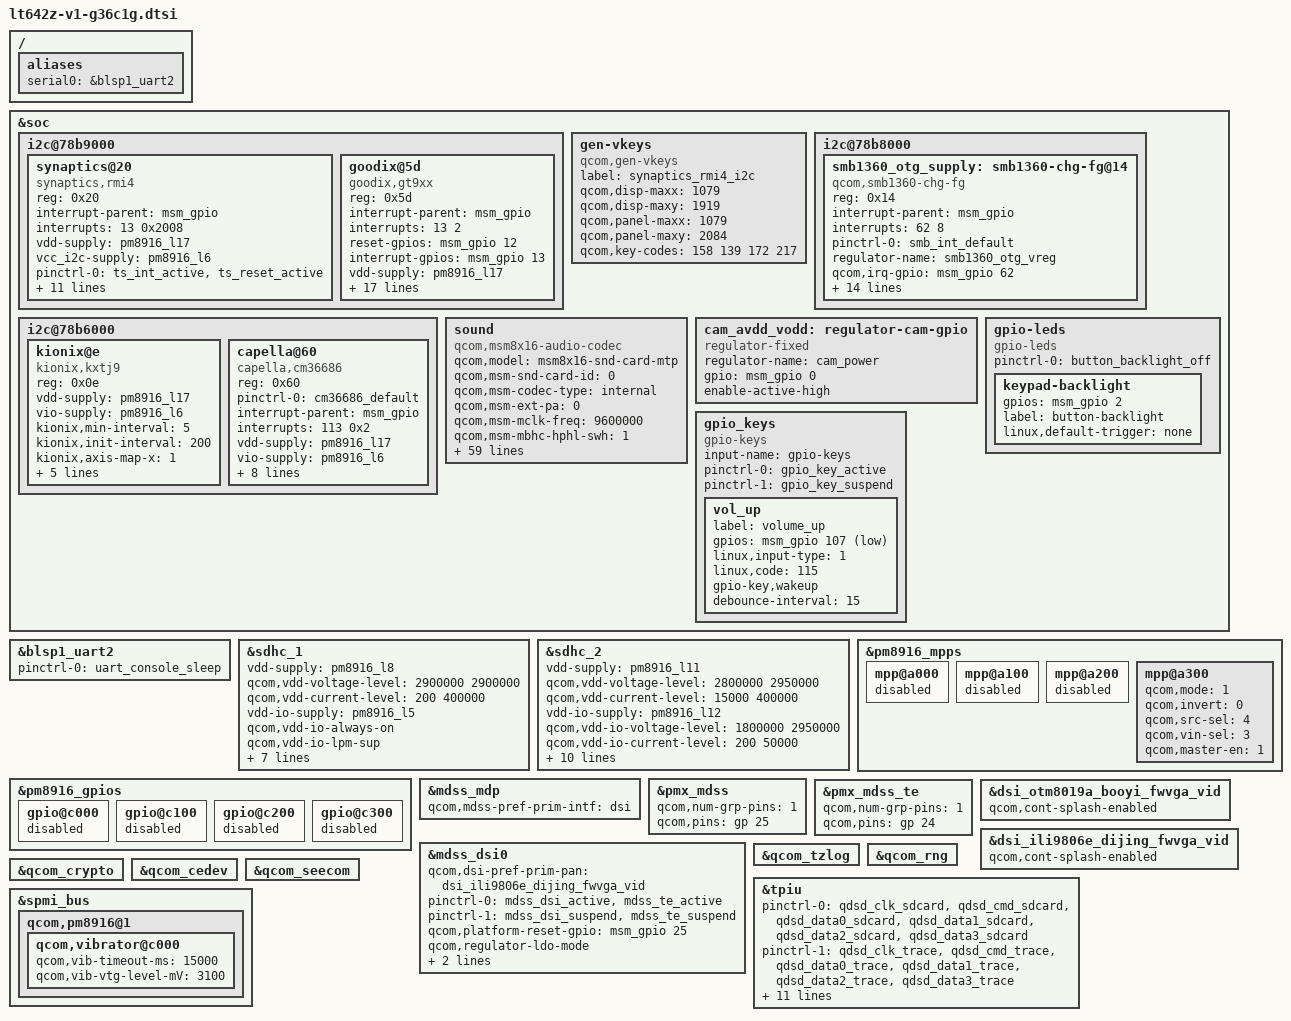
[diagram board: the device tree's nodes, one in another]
/* Copyright (c) 2014, The Linux Foundation. All rights reserved.
 *
 * This program is free software; you can redistribute it and/or modify
 * it under the terms of the GNU General Public License version 2 and
 * only version 2 as published by the Free Software Foundation.
 *
 * This program is distributed in the hope that it will be useful,
 * but WITHOUT ANY WARRANTY; without even the implied warranty of
 * MERCHANTABILITY or FITNESS FOR A PARTICULAR PURPOSE.  See the
 * GNU General Public License for more details.
 */

#include "msm8916-pinctrl.dtsi"
#include "msm8916-camera-sensor-mtp.dtsi"

/ {
	aliases {
		serial0 = &blsp1_uart2;
	};
};

&soc {
	i2c@78b9000 { /* BLSP1 QUP5 */
		synaptics@20 {
			compatible = "synaptics,rmi4";
			reg = <0x20>;
			interrupt-parent = <&msm_gpio>;
			interrupts = <13 0x2008>;
			vdd-supply = <&pm8916_l17>;
			vcc_i2c-supply = <&pm8916_l6>;
			/* pins used by touchscreen */
			pinctrl-names = "pmx_ts_active","pmx_ts_suspend","pmx_ts_suspend";
			pinctrl-0 = <&ts_int_active &ts_reset_active>;
			pinctrl-1 = <&ts_int_suspend &ts_reset_suspend>;
			pinctrl-2 = <&ts_release>;
			synaptics,display-coords = <0 0 1079 1919>;
			synaptics,panel-coords = <0 0 1079 2084>;
			synaptics,irq-gpio = <&msm_gpio 13 0x2008>;
			synaptics,reset-gpio = <&msm_gpio 12 0x0>;
			synaptics,i2c-pull-up;
			synaptics,power-down;
			synaptics,disable-gpios;
			/* Underlying clocks used by secure touch */
			clocks = <&clock_gcc clk_gcc_blsp1_ahb_clk>,
			 <&clock_gcc clk_gcc_blsp1_qup5_i2c_apps_clk>;
			clock-names = "iface_clk", "core_clk";
		};
	        goodix@5d {
			compatible = "goodix,gt9xx";
			reg = <0x5d>;
			interrupt-parent = <&msm_gpio>;
			interrupts = <13 2>;
			reset-gpios = <&msm_gpio 12 0x00>;
			interrupt-gpios = <&msm_gpio 13 0x00>;
			vdd-supply = <&pm8916_l17>;
			vcc-i2c-supply = <&pm8916_l6>;
			pinctrl-names = "pmx_ts_active","pmx_ts_suspend";
			pinctrl-0 = <&ts_int_active &ts_reset_active>;
			pinctrl-1 = <&ts_int_suspend &ts_reset_suspend>;
			goodix,panel-coords = <0 0 480 854>;
			goodix,display-coords = <0 0 480 854>;
			goodix,button-map= <139 172 158>;
			goodix,product-id = "9157";
			goodix,rawdata-key0 = <14 8 4100 1200>;
			goodix,rawdata-key1 = <14 8 2000 600>;
			goodix,cfg-data0 = [//dijing
				 42 E0 01 56 03 0A 05 41 01 08 28 08 50 32 03 05 00 00 1D 7E 00 00 00 00 00 00 00 8A 29 0A 28 2A D3 07 00 00 00 9B 33 1D 00 00 00 00 00 00 00 32 00 00 2B 28 46 94 D5 02 07 14 00 04 7A 2A 00 6E 2F 00 65 34 00 5A 3B 00 51 42 00 51 10 30 48 00 F0 4A 3A FF FF 27 00 00 00 00 00 00 00 00 00 00 00 00 00 00 00 00 00 00 00 00 00 00 05 00 46 28 02 04 06 08 0A 0C 0E 10 12 14 FF FF FF FF 1F FF FF FF FF FF FF FF FF 00 00 19 00 00 FF FF 22 21 20 1F 1E 1D 1C 16 18 04 12 0F 08 0A 0C 06 10 02 00 FF FF FF FF FF FF FF 00 00 00 FC FF FF FF FF FF FF FF CF FF FF FF FF 13 01];

			goodix,cfg-data1 = [//zhenghai
				 42 E0 01 56 03 0A 05 41 01 08 28 08 50 32 03 05 00 00 1D 7E 00 00 00 00 00 00 00 8A 29 0A 28 2A D3 07 00 00 00 9B 33 1D 00 00 00 00 00 00 00 32 00 00 2B 28 46 94 D5 02 07 14 00 04 7A 2A 00 6E 2F 00 65 34 00 5A 3B 00 51 42 00 51 10 30 48 00 F0 4A 3A FF FF 27 00 00 00 00 00 00 00 00 00 00 00 00 00 00 00 00 00 00 00 00 00 00 05 00 46 28 02 04 06 08 0A 0C 0E 10 12 14 FF FF FF FF 1F FF FF FF FF FF FF FF FF 00 00 19 00 00 FF FF 22 21 20 1F 1E 1D 1C 16 18 04 12 0F 08 0A 0C 06 10 02 00 FF FF FF FF FF FF FF 00 00 00 FC FF FF FF FF FF FF FF CF FF FF FF FF 13 01];
				 
			goodix,test-data0 = [//dijing
 				00 D0 02 00 05 0A 05 41 01 08 28 08 50 32 03 05 00 00 00 00 00 00 00 00 00 00 00 8A 29 0A 64 66 D3 07 00 00 00 9B 02 1D 00 00 00 00 00 00 00 32 00 00 00 28 46 94 55 02 07 14 00 04 7A 2A 00 6E 2F 00 65 34 00 5A 3B 00 51 42 00 51 10 30 48 00 F0 4A 3A FF FF 27 00 00 00 00 00 00 00 00 00 00 00 00 00 00 00 00 00 00 00 00 00 00 05 00 00 00 02 04 06 08 0A 0C 0E 10 12 14 FF FF FF FF 1F FF FF FF FF FF FF FF FF 00 FF FF FF 0F FF 00 22 21 20 1F 1E 1D 1C 16 18 04 12 0F 08 0A 0C 06 10 02 00 FF FF FF FF FF FF FF 00 00 00 FC FF FF FF FF FF FF FF CF FF FF FF FF 31 01];

			goodix,test-data1 = [//zhenghai
				 00 D0 02 00 05 0A 05 41 01 08 28 08 50 32 03 05 00 00 00 00 00 00 00 00 00 00 00 8A 29 0A 64 66 D3 07 00 00 00 9B 02 1D 00 00 00 00 00 00 00 32 00 00 00 28 46 94 55 02 07 14 00 04 7A 2A 00 6E 2F 00 65 34 00 5A 3B 00 51 42 00 51 10 30 48 00 F0 4A 3A FF FF 27 00 00 00 00 00 00 00 00 00 00 00 00 00 00 00 00 00 00 00 00 00 00 05 00 00 00 02 04 06 08 0A 0C 0E 10 12 14 FF FF FF FF 1F FF FF FF FF FF FF FF FF 00 FF FF FF 0F FF 00 22 21 20 1F 1E 1D 1C 16 18 04 12 0F 08 0A 0C 06 10 02 00 FF FF FF FF FF FF FF 00 00 00 FC FF FF FF FF FF FF FF CF FF FF FF FF 31 01];
		};
	};

	gen-vkeys {
		compatible = "qcom,gen-vkeys";
		label = "synaptics_rmi4_i2c";
		qcom,disp-maxx = <1079>;
		qcom,disp-maxy = <1919>;
		qcom,panel-maxx = <1079>;
		qcom,panel-maxy = <2084>;
		qcom,key-codes = <158 139 172 217>;
	};

	i2c@78b8000 {
		smb1360_otg_supply: smb1360-chg-fg@14 {
			compatible = "qcom,smb1360-chg-fg";
			reg = <0x14>;
			interrupt-parent = <&msm_gpio>;
			interrupts = <62 8>;
			pinctrl-names = "default";
			pinctrl-0 = <&smb_int_default>;
			regulator-name = "smb1360_otg_vreg";
			qcom,irq-gpio = <&msm_gpio 62 0x8>;
			qcom,chg-inhibit-disabled;
			qcom,float-voltage-mv = <4350>;
			qcom,iterm-ma = <100>;
			qcom,recharge-thresh-mv = <100>;
			qcom,thermal-mitigation = <1500 700 600 0>;
			qcom,charging-timeout = <1536>;
			qcom,fg-cutoff-voltage-mv = <3400>;
			qcom,fg-voltage-empty-mv = <3250>;
			qcom,fg-batt-capacity-mah = <2500>;
			qcom,fg-cc-soc-coeff = <0x828E>;	
			qcom,fg-auto-recharge-soc = <99>;
			qcom,fg-reset-thresold-mv = <25>;
			qcom,shdn-after-pwroff;
      qcom,fg-reset-at-pon;
		};
	};
	i2c@78b6000 { /* BLSP1 QUP2 */
		kionix@e {
			compatible = "kionix,kxtj9";
			reg = <0x0e>;
			vdd-supply = <&pm8916_l17>;
			vio-supply = <&pm8916_l6>;
			kionix,min-interval = <5>;
			kionix,init-interval = <200>;
			kionix,axis-map-x = <1>;
			kionix,axis-map-y = <0>;
			kionix,axis-map-z = <2>;
			kionix,g-range = <2>;
			kionix,negate-x;
			/*kionix,negate-y;*/
			/*kionix,negate-z;*/
			kionix,res-12bit;
		};

		capella@60 {
			compatible = "capella,cm36686";
			reg = <0x60>;
			pinctrl-names = "default";
			pinctrl-0 = <&cm36686_default>;
			interrupt-parent = <&msm_gpio>;
			interrupts = <113 0x2>;
			vdd-supply = <&pm8916_l17>;
			vio-supply = <&pm8916_l6>;
			capella,interrupt-gpio =<&msm_gpio 113 0x2>;
			capella,ps_duty = <0>;
			/*
			 * CM36283 & CM36686
			 * 0 -- 1/40; 1 -- 1/80; 2 -- 1/160; 3 -- 1/320;
			 */
			capella,ps_it = <2>;
			/*
			 *CM3686
			 * Default set to 1.
			 * 0 -- 1T; 1 -- 1.5T; 2 -- 2T; 3 -- 2.5T;
			 * 4 -- 3T; 5 -- 3.5T; 6 -- 4T; 7 -- 8T;
			 */
			capella,ps_led_drv = <2>;
			/*
			 * This para in CM36686
			 * Default set to 2.
			 * 0 -- 50mA; 1 -- 75mA; 2 -- 100mA; 3 -- 120mA;
			 * 4 -- 140mA; 5 -- 160mA; 6 -- 180mA; 7 -- 200mA;
			 */
			capella,ps_close_thd_set = <48>;
			capella,ps_away_thd_set = <14>;
			capella,als_range = <0>;
			/*
			 * 0 -- 80ms; 1 -- 160ms; 2 -- 320ms; 3 -- 640ms;
			 * Dividor:
			 * CM36283, 80;
			 * CM36682, 100;
			 * CM36686, 100.
			 */
			capella,als_fittness = <10>;
			/*
			 * This para using for fix the mechinical diff about TP lens.
			 * Default set to 10.
			 */
		};

	};

	sound {
		compatible = "qcom,msm8x16-audio-codec";
		qcom,model = "msm8x16-snd-card-mtp";
		qcom,msm-snd-card-id = <0>;
		qcom,msm-codec-type = "internal";
		qcom,msm-ext-pa = <0>;
		qcom,msm-mclk-freq = <9600000>;
		qcom,msm-mbhc-hphl-swh = <1>;
		qcom,msm-mbhc-gnd-swh = <0>;
		qcom,msm-micbias1-ext-cap;
		qcom,msm-micbias2-ext-cap;
		qcom,msm-hs-micbias-type = "external";
		qcom,audio-routing =
			"RX_BIAS", "MCLK",
			"SPK_RX_BIAS", "MCLK",
			"INT_LDO_H", "MCLK",
			"MIC BIAS External", "Handset Mic",
			"MIC BIAS External2", "Headset Mic",
			"MIC BIAS External", "Secondary Mic",
			"AMIC1", "MIC BIAS External",
			"AMIC2", "MIC BIAS External2",
			"AMIC3", "MIC BIAS External",
			"DMIC1", "MIC BIAS Internal1",
			"MIC BIAS Internal1", "Digital Mic1",
			"DMIC2", "MIC BIAS Internal1",
			"MIC BIAS Internal1", "Digital Mic2";
		pinctrl-names = "cdc_lines_act",
				"cdc_lines_sus",
				"cdc_lines_sec_ext_act",
				"cdc_lines_sec_ext_sus",
				"cross_conn_det_act",
				"cross_conn_det_sus";
		pinctrl-0 = <&cdc_pdm_lines_act>;
		pinctrl-1 = <&cdc_pdm_lines_sus>;
		pinctrl-2 = <&cdc_pdm_lines_act &cdc_ext_pa_act
						&cdc_ext_pa_ws_act>;
		pinctrl-3 = <&cdc_pdm_lines_sus &cdc_ext_pa_sus
						&cdc_ext_pa_ws_sus>;
		pinctrl-4 = <&cross_conn_det_act>;
		pinctrl-5 = <&cross_conn_det_sus>;
		qcom,cdc-us-euro-gpios = <&msm_gpio 120 0>;
		qcom,ext-spk-pa-gpio = <&msm_gpio 1 0>;
		qcom,headset-switch-gpio = <&msm_gpio 109 0>;
		asoc-platform = <&pcm0>, <&pcm1>, <&voip>, <&voice>,
				<&loopback>, <&compress>, <&hostless>,
				<&afe>, <&lsm>, <&routing>, <&lpa>;
		asoc-platform-names = "msm-pcm-dsp.0", "msm-pcm-dsp.1",
				"msm-voip-dsp", "msm-pcm-voice", "msm-pcm-loopback",
				"msm-compress-dsp", "msm-pcm-hostless", "msm-pcm-afe",
				"msm-lsm-client", "msm-pcm-routing", "msm-pcm-lpa";
		asoc-cpu = <&dai_pri_auxpcm>, <&dai_hdmi>,
				<&dai_mi2s0>, <&dai_mi2s1>, <&dai_mi2s2>, <&dai_mi2s3>,
				<&sb_0_rx>, <&sb_0_tx>, <&sb_1_rx>, <&sb_1_tx>,
				<&sb_3_rx>, <&sb_3_tx>, <&sb_4_rx>, <&sb_4_tx>,
				<&bt_sco_rx>, <&bt_sco_tx>, <&int_fm_rx>, <&int_fm_tx>,
				<&afe_pcm_rx>, <&afe_pcm_tx>, <&afe_proxy_rx>, <&afe_proxy_tx>,
				<&incall_record_rx>, <&incall_record_tx>, <&incall_music_rx>,
				<&incall_music_2_rx>;
		asoc-cpu-names = "msm-dai-q6-auxpcm.1", "msm-dai-q6-hdmi.8",
				"msm-dai-q6-mi2s.0", "msm-dai-q6-mi2s.1",
				"msm-dai-q6-mi2s.2", "msm-dai-q6-mi2s.3",
				"msm-dai-q6-dev.16384", "msm-dai-q6-dev.16385",
				"msm-dai-q6-dev.16386", "msm-dai-q6-dev.16387",
				"msm-dai-q6-dev.16390", "msm-dai-q6-dev.16391",
				"msm-dai-q6-dev.16392", "msm-dai-q6-dev.16393",
				"msm-dai-q6-dev.12288", "msm-dai-q6-dev.12289",
				"msm-dai-q6-dev.12292", "msm-dai-q6-dev.12293",
				"msm-dai-q6-dev.224", "msm-dai-q6-dev.225",
				"msm-dai-q6-dev.241", "msm-dai-q6-dev.240",
				"msm-dai-q6-dev.32771", "msm-dai-q6-dev.32772",
				"msm-dai-q6-dev.32773", "msm-dai-q6-dev.32770";
		asoc-codec = <&stub_codec>, <&pm8916_tombak_dig>;
		asoc-codec-names = "msm-stub-codec.1", "tombak_codec";
	};
	cam_avdd_vodd: regulator-cam-gpio {
		compatible = "regulator-fixed";
	    regulator-name = "cam_power";
		gpio = <&msm_gpio 0 0>;
		enable-active-high;
	};
  gpio-leds {
		compatible = "gpio-leds";
		status = "okay";
		pinctrl-names = "default";
		pinctrl-0 = <&button_backlight_off>;
		keypad-backlight {
			gpios = <&msm_gpio 2 0x00>;
			label = "button-backlight";
			linux,default-trigger = "none";
		};
	};
};

&blsp1_uart2 {
	status = "ok";
	pinctrl-names = "default";
	pinctrl-0 = <&uart_console_sleep>;
};

&soc {
	gpio_keys {
		compatible = "gpio-keys";
		input-name = "gpio-keys";
		pinctrl-names = "tlmm_gpio_key_active","tlmm_gpio_key_suspend";
		pinctrl-0 = <&gpio_key_active>;
		pinctrl-1 = <&gpio_key_suspend>;
/*delete conflictive gpio with platform by hisense 2014.12.19
		camera_focus {
			label = "camera_focus";
			gpios = <&msm_gpio 108 0x1>;
			linux,input-type = <1>;
			linux,code = <0x210>;
			gpio-key,wakeup;
			debounce-interval = <15>;
		};

		camera_snapshot {
			label = "camera_snapshot";
			gpios = <&msm_gpio 109 0x1>;
			linux,input-type = <1>;
			linux,code = <0x2fe>;
			gpio-key,wakeup;
			debounce-interval = <15>;
		};
*/
		vol_up {
			label = "volume_up";
			gpios = <&msm_gpio 107 0x1>;
			linux,input-type = <1>;
			linux,code = <115>;
			gpio-key,wakeup;
			debounce-interval = <15>;
		};
	};
};

&sdhc_1 {
	vdd-supply = <&pm8916_l8>;
	qcom,vdd-voltage-level = <2900000 2900000>;
	qcom,vdd-current-level = <200 400000>;

	vdd-io-supply = <&pm8916_l5>;
	qcom,vdd-io-always-on;
	qcom,vdd-io-lpm-sup;
	qcom,vdd-io-voltage-level = <1800000 1800000>;
	qcom,vdd-io-current-level = <200 60000>;

	pinctrl-names = "active", "sleep";
	pinctrl-0 = <&sdc1_clk_on &sdc1_cmd_on &sdc1_data_on>;
	pinctrl-1 = <&sdc1_clk_off &sdc1_cmd_off &sdc1_data_off>;

	qcom,nonremovable;

	status = "ok";
};

&sdhc_2 {
	vdd-supply = <&pm8916_l11>;
	qcom,vdd-voltage-level = <2800000 2950000>;
	qcom,vdd-current-level = <15000 400000>;

	vdd-io-supply = <&pm8916_l12>;
	qcom,vdd-io-voltage-level = <1800000 2950000>;
	qcom,vdd-io-current-level = <200 50000>;

	pinctrl-names = "active", "sleep";
	pinctrl-0 = <&sdc2_clk_on &sdc2_cmd_on &sdc2_data_on &sdc2_cd_on>;
	pinctrl-1 = <&sdc2_clk_off &sdc2_cmd_off &sdc2_data_off &sdc2_cd_off>;

	#address-cells = <0>;
	interrupt-parent = <&sdhc_2>;
	interrupts = <0 1 2>;
	#interrupt-cells = <1>;
	interrupt-map-mask = <0xffffffff>;
	interrupt-map = <0 &intc 0 125 0
			1 &intc 0 221 0
			2 &msm_gpio 38 0>;
	interrupt-names = "hc_irq", "pwr_irq", "status_irq";
	cd-gpios = <&msm_gpio 38 0x1>;

	status = "ok";
};

&pm8916_mpps {
	mpp@a000 { /* MPP 1 */
		/* VDD_PX */
		status = "disabled";
	};

	mpp@a100 { /* MPP 2 */
		/* HR LED */
		status = "disabled";
	};

	mpp@a200 { /* MPP 3 */
		/* VREF DAC */
		status = "disabled";
	};

	mpp@a300 { /* MPP 4 */
		/* Backlight PWM */
		qcom,mode = <1>;		/* Digital output */
		qcom,invert = <0>;		/* Disable invert */
		qcom,src-sel = <4>;		/* DTEST1 */
		qcom,vin-sel = <3>;		/* VREG_L6 */
		qcom,master-en = <1>;		/* Enable MPP */
	};
};

&pm8916_gpios {
	gpio@c000 { /* GPIO 1 */
		/* Battery UICC Alarm */
		status = "disabled";
	};

	gpio@c100 { /* GPIO 2 */
		/* NFC_CLK_REQ  Qcom NFC not used*/
    		status = "disabled";
	};

	gpio@c200 { /* GPIO 3 */
		/* External regulator control for WTR */
		status = "disabled";
	};

	gpio@c300 { /* GPIO 4 */
		/* External regulator control for APC */
		status = "disabled";
	};
};

#include "dsi-panel-otm8019a-booyi-fwvga-video.dtsi"
#include "dsi-panel-ili9806e-dijing-fwvga-video.dtsi"


&mdss_mdp {
	qcom,mdss-pref-prim-intf = "dsi";
};



&pmx_mdss {
	qcom,num-grp-pins = <1>;
	qcom,pins = <&gp 25>;
};

&pmx_mdss_te {
	qcom,num-grp-pins = <1>;
	qcom,pins = <&gp 24>;
};

&mdss_dsi0 {
	qcom,dsi-pref-prim-pan = <&dsi_otm8019a_booyi_fwvga_vid>;
	qcom,dsi-pref-prim-pan = <&dsi_ili9806e_dijing_fwvga_vid>;
	pinctrl-names = "mdss_default", "mdss_sleep";
	pinctrl-0 = <&mdss_dsi_active &mdss_te_active>;
	pinctrl-1 = <&mdss_dsi_suspend &mdss_te_suspend>;

	qcom,platform-reset-gpio = <&msm_gpio 25 0>;
	qcom,regulator-ldo-mode;  
	qcom,platform-regulator-settings = [02 09 03 00 20 00 01]; 
};

&dsi_otm8019a_booyi_fwvga_vid {
       qcom,cont-splash-enabled;
};
&dsi_ili9806e_dijing_fwvga_vid {
       qcom,cont-splash-enabled;
};

&qcom_tzlog {
	status = "okay";
};

&qcom_rng {
	status = "okay";
};

&qcom_crypto {
	status = "okay";
};

&qcom_cedev {
	status = "okay";
};

&qcom_seecom {
	status = "okay";
};

/* CoreSight */
&tpiu {
      pinctrl-names = "sdcard", "trace", "swduart",
		      "swdtrc", "jtag", "spmi";
       /* NIDnT */
      pinctrl-0 = <&qdsd_clk_sdcard &qdsd_cmd_sdcard
                  &qdsd_data0_sdcard &qdsd_data1_sdcard
                  &qdsd_data2_sdcard &qdsd_data3_sdcard>;
      pinctrl-1 = <&qdsd_clk_trace &qdsd_cmd_trace
                  &qdsd_data0_trace &qdsd_data1_trace
                  &qdsd_data2_trace &qdsd_data3_trace>;
      pinctrl-2 = <&qdsd_cmd_swduart &qdsd_data0_swduart
                  &qdsd_data1_swduart &qdsd_data2_swduart
                  &qdsd_data3_swduart>;
      pinctrl-3 = <&qdsd_clk_swdtrc &qdsd_cmd_swdtrc
                  &qdsd_data0_swdtrc &qdsd_data1_swdtrc
                  &qdsd_data2_swdtrc &qdsd_data3_swdtrc>;
      pinctrl-4 = <&qdsd_cmd_jtag &qdsd_data0_jtag
                  &qdsd_data1_jtag &qdsd_data2_jtag
                  &qdsd_data3_jtag>;
      pinctrl-5 = <&qdsd_clk_spmi &qdsd_cmd_spmi
                  &qdsd_data0_spmi &qdsd_data3_spmi>;
};

&spmi_bus {
	qcom,pm8916@1 {
		qcom,vibrator@c000 {
			status = "okay";
			qcom,vib-timeout-ms = <15000>;
			qcom,vib-vtg-level-mV = <3100>;
		};
	};
};
